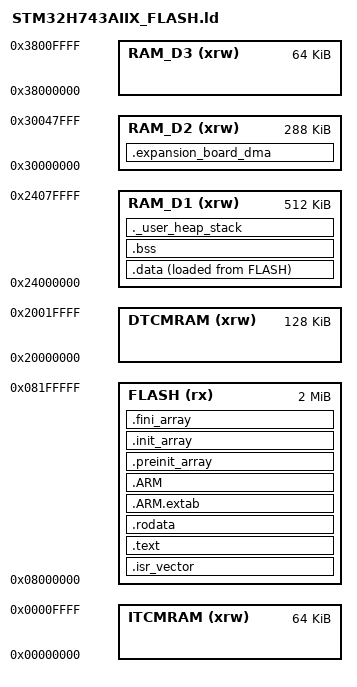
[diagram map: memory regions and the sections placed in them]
/*
******************************************************************************
**
**  File        : LinkerScript.ld
**
**  Author      : STM32CubeIDE
**
**  Abstract    : Linker script for STM32H7 series
**                2048Kbytes FLASH and 1056Kbytes RAM
**
**                Set heap size, stack size and stack location according
**                to application requirements.
**
**                Set memory bank area and size if external memory is used.
**
**  Target      : STMicroelectronics STM32
**
**  Distribution: The file is distributed as is, without any warranty
**                of any kind.
**
*****************************************************************************
** @attention
**
** Copyright (c) 2023 STMicroelectronics.
** All rights reserved.
**
** This software is licensed under terms that can be found in the LICENSE file
** in the root directory of this software component.
** If no LICENSE file comes with this software, it is provided AS-IS.
**
****************************************************************************
*/

/* Entry Point */
ENTRY(Reset_Handler)

/* Highest address of the user mode stack */
_estack = ORIGIN(RAM_D1) + LENGTH(RAM_D1);    /* end of RAM */
/* Generate a link error if heap and stack don't fit into RAM */
_Min_Heap_Size = 0x200;      /* required amount of heap  */
_Min_Stack_Size = 0x400; /* required amount of stack */

/* Specify the memory areas */
MEMORY
{
  FLASH (rx)     : ORIGIN = 0x08000000, LENGTH = 2048K
  DTCMRAM (xrw)  : ORIGIN = 0x20000000, LENGTH = 128K
  RAM_D1 (xrw)   : ORIGIN = 0x24000000, LENGTH = 512K
  RAM_D2 (xrw)   : ORIGIN = 0x30000000, LENGTH = 288K
  RAM_D3 (xrw)   : ORIGIN = 0x38000000, LENGTH = 64K
  ITCMRAM (xrw)  : ORIGIN = 0x00000000, LENGTH = 64K
}

/* Define output sections */
SECTIONS
{
  /* The startup code goes first into FLASH */
  .isr_vector :
  {
    . = ALIGN(4);
    KEEP(*(.isr_vector)) /* Startup code */
    . = ALIGN(4);
  } >FLASH

  /* The program code and other data goes into FLASH */
  .text :
  {
    . = ALIGN(4);
    *(.text)           /* .text sections (code) */
    *(.text*)          /* .text* sections (code) */
    *(.glue_7)         /* glue arm to thumb code */
    *(.glue_7t)        /* glue thumb to arm code */
    *(.eh_frame)

    KEEP (*(.init))
    KEEP (*(.fini))

    . = ALIGN(4);
    _etext = .;        /* define a global symbols at end of code */
  } >FLASH

  /* Constant data goes into FLASH */
  .rodata :
  {
    . = ALIGN(4);
    *(.rodata)         /* .rodata sections (constants, strings, etc.) */
    *(.rodata*)        /* .rodata* sections (constants, strings, etc.) */
    . = ALIGN(4);
  } >FLASH

  .ARM.extab   : { *(.ARM.extab* .gnu.linkonce.armextab.*) } >FLASH
  .ARM : {
    __exidx_start = .;
    *(.ARM.exidx*)
    __exidx_end = .;
  } >FLASH

  .preinit_array     :
  {
    PROVIDE_HIDDEN (__preinit_array_start = .);
    KEEP (*(.preinit_array*))
    PROVIDE_HIDDEN (__preinit_array_end = .);
  } >FLASH

  .init_array :
  {
    PROVIDE_HIDDEN (__init_array_start = .);
    KEEP (*(SORT(.init_array.*)))
    KEEP (*(.init_array*))
    PROVIDE_HIDDEN (__init_array_end = .);
  } >FLASH

  .fini_array :
  {
    PROVIDE_HIDDEN (__fini_array_start = .);
    KEEP (*(SORT(.fini_array.*)))
    KEEP (*(.fini_array*))
    PROVIDE_HIDDEN (__fini_array_end = .);
  } >FLASH

  /* used by the startup to initialize data */
  _sidata = LOADADDR(.data);

  /* Initialized data sections goes into RAM, load LMA copy after code */
  .data :
  {
    . = ALIGN(4);
    _sdata = .;        /* create a global symbol at data start */
    *(.data)           /* .data sections */
    *(.data*)          /* .data* sections */
    *(.RamFunc)        /* .RamFunc sections */
    *(.RamFunc*)       /* .RamFunc* sections */

    . = ALIGN(4);
    _edata = .;        /* define a global symbol at data end */
  } >RAM_D1 AT> FLASH

  /* Uninitialized data section */
  . = ALIGN(4);
  .bss :
  {
    /* This is used by the startup in order to initialize the .bss section */
    _sbss = .;         /* define a global symbol at bss start */
    __bss_start__ = _sbss;
    *(.bss)
    *(.bss*)
    *(COMMON)

    . = ALIGN(4);
    _ebss = .;         /* define a global symbol at bss end */
    __bss_end__ = _ebss;
  } >RAM_D1
  
  
  /* 1NE Recognition */
  .expansion_board_dma (NOLOAD) :
  {
    . = ABSOLUTE(0x30000000);
    /* I2C1(3Axis IMU) & I2C2(6Axis IMU) */
    *(.i2c1RxBuff)
    *(.i2c2RxBuff)
    
    /* Sequential Notation for ADC */
    /* ADC1(R_EMG_1, R_EMG_2, L_FSR_1, L_FSR_2) -> TOTAL: 4 */
    *(.adc1DmaBuff)
    /* ADC2(R_EMG_3, R_EMG_4) -> TOTAL: 2 */
    *(.adc2DmaBuff)
    /* ADC3(L_FSR_3, L_FSR_4, L_EMG_3, L_EMG_1, R_FSR_3, R_FSR_1, L_EMG_4, L_EMG_2, R_FSR_4, R_FSR_2) -> TOTAL: 10 */
    *(.adc3DmaBuff)
    
    /* UART7 & 8 for IMU */
    *(.uart7DmaRx1Buff)
    *(.uart7DmaRx2Buff)
    *(.uart7DmaRx3Buff)
    *(.uart7DmaRx4Buff)
    *(.uart8DmaRx1Buff)
    *(.uart8DmaRx2Buff)
    *(.uart8DmaRx3Buff)
    *(.uart8DmaRx4Buff)
    *(.uart8DmaRx5Buff)
    *(.uart8DmaRx6Buff)
    
  } >RAM_D2
  

  /* User_heap_stack section, used to check that there is enough RAM left */
  ._user_heap_stack :
  {
    . = ALIGN(8);
    PROVIDE ( end = . );
    PROVIDE ( _end = . );
    . = . + _Min_Heap_Size;
    . = . + _Min_Stack_Size;
    . = ALIGN(8);
  } >RAM_D1

  /* Remove information from the standard libraries */
  /DISCARD/ :
  {
    libc.a ( * )
    libm.a ( * )
    libgcc.a ( * )
  }

  .ARM.attributes 0 : { *(.ARM.attributes) }
}


